VERSION "1.4"

NS_ :

BS_:

BU_: Engine Gateway Dashboard Transmission

VAL_TABLE_ GearPosition 7 "Invalid" 6 "Reverse" 5 "Fifth" 4 "Fourth" 3 "Third" 2 "Second" 1 "First" 0 "Neutral" ;
VAL_TABLE_ OnOff 1 "On" 0 "Off" ;

BO_ 2566844672 CruiseControl: 8 Dashboard
 SG_ SetSpeed : 0|8@1+ (1,0) [0|250] "km/h"  Engine

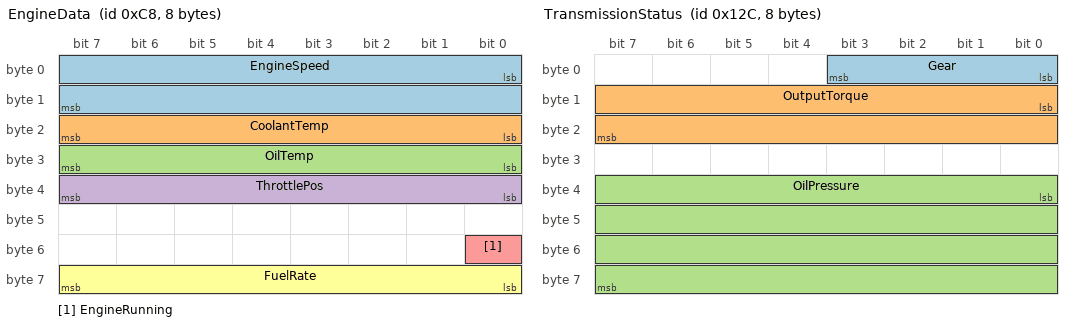
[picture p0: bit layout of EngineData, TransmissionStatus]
BO_ 200 EngineData: 8 Engine
 SG_ EngineSpeed : 0|16@1+ (0.125,0) [0|16383.75] "rpm"  Dashboard,Gateway
 SG_ CoolantTemp : 16|8@1+ (1,-40) [-40|215] "degC"  Dashboard
 SG_ OilTemp : 24|8@1+ (1,-40) [-40|215] "degC"  Dashboard
 SG_ ThrottlePos : 39|8@0- (0.5,0) [-64|63.5] "%"  Gateway
 SG_ EngineRunning : 48|1@1+ (1,0) [0|1] ""  Dashboard,Transmission
 SG_ FuelRate : 56|8@1+ (0.2,0) [0|51] "l/h"  Dashboard

BO_ 300 TransmissionStatus: 8 Transmission
 SG_ Gear : 0|4@1+ (1,0) [0|7] ""  Dashboard,Engine
 SG_ OutputTorque : 8|16@1- (0.1,0) [-3276.8|3276.7] "Nm"  Engine
 SG_ OilPressure : 32|32@1- (1,0) [0|100] "bar"  Dashboard

BO_ 1024 Diagnostics: 8 Gateway
 SG_ DiagMux M : 0|8@1+ (1,0) [0|255] ""  Engine,Transmission
 SG_ BatteryVoltage m1 : 8|16@1+ (0.001,0) [0|65.535] "V"  Engine
 SG_ ErrorCount m1 : 24|8@1+ (1,0) [0|255] ""  Engine
 SG_ SoftwareVersion m2 : 8|32@1+ (1,0) [0|4294967295] ""  Transmission
 SG_ HeaterState m2 : 40|1@1+ (1,0) [0|1] ""  Transmission

BO_TX_BU_ 1024 : Gateway,Dashboard;

CM_ "Powertrain CAN, 500 kbit/s";
CM_ BU_ Engine "Engine control unit";
CM_ BO_ 200 "Engine state, sent every 10 ms";
CM_ SG_ 200 EngineSpeed "Engine speed from crank sensor";
CM_ SG_ 200 FuelRate "Injected fuel per hour";
CM_ SG_ 1024 DiagMux "Selects the diagnostic page";
BA_DEF_ BO_  "GenMsgCycleTime" INT 0 10000;
BA_DEF_ BO_  "GenMsgSendType" ENUM  "Cyclic","Event","IfActive","NoMsgSendType";
BA_DEF_ SG_  "GenSigStartValue" FLOAT 0 1e+10;
BA_DEF_ BU_  "NodeLayerModules" STRING ;
BA_DEF_  "BusType" STRING ;
BA_DEF_DEF_  "GenMsgCycleTime" 0;
BA_DEF_DEF_  "GenMsgSendType" "NoMsgSendType";
BA_DEF_DEF_  "GenSigStartValue" 0;
BA_DEF_DEF_  "NodeLayerModules" "";
BA_DEF_DEF_  "BusType" "CAN";
BA_ "NodeLayerModules" BU_ Engine "CANoeILNLVector.dll";
BA_ "GenMsgCycleTime" BO_ 200 10;
BA_ "GenMsgSendType" BO_ 200 0;
BA_ "GenMsgCycleTime" BO_ 300 100;
BA_ "GenMsgSendType" BO_ 300 0;
BA_ "GenMsgSendType" BO_ 1024 1;
BA_ "GenSigStartValue" SG_ 200 CoolantTemp 40;
VAL_ 200 EngineRunning 1 "Running" 0 "Off" ;
VAL_ 300 Gear 7 "Invalid" 6 "Reverse" 5 "Fifth" 4 "Fourth" 3 "Third" 2 "Second" 1 "First" 0 "Neutral" ;
VAL_ 1024 HeaterState 1 "On" 0 "Off" ;
SIG_GROUP_ 200 Temps 1 : CoolantTemp OilTemp;
SIG_VALTYPE_ 300 OilPressure : 1;
